VERSION "GT86 bus: what the GT86-ISF gateway sends (generated by tools/generate.py)"

NS_ :

BS_:

BU_: GATEWAY ADU GT86

BO_ 208 GT86_GSensor: 8 GATEWAY

BO_ 209 GT86_VehicleSpeed: 8 GATEWAY
 SG_ VehicleSpeed : 0|16@1+ (0.0565,0) [0|3702.73] "km/h" GT86

BO_ 210 GT86_Unknown_D2: 8 GATEWAY

BO_ 211 GT86_LightStatus: 8 GATEWAY

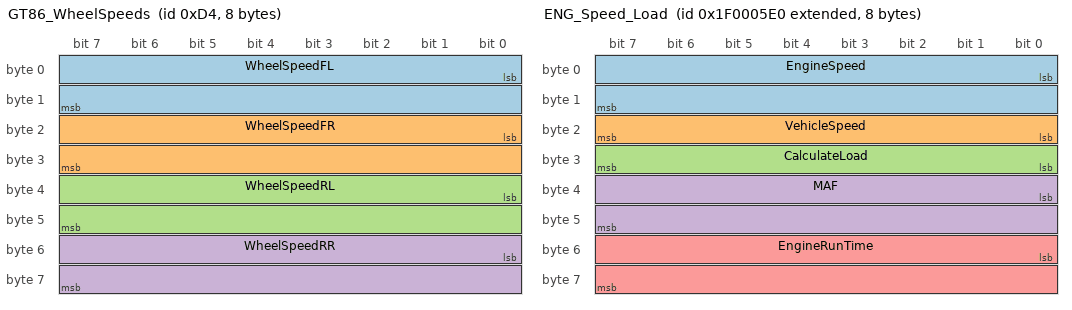
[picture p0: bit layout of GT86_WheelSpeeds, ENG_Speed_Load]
BO_ 212 GT86_WheelSpeeds: 8 GATEWAY
 SG_ WheelSpeedFL : 0|16@1+ (0.0565,0) [0|3702.73] "km/h" GT86
 SG_ WheelSpeedFR : 16|16@1+ (0.0565,0) [0|3702.73] "km/h" GT86
 SG_ WheelSpeedRL : 32|16@1+ (0.0565,0) [0|3702.73] "km/h" GT86
 SG_ WheelSpeedRR : 48|16@1+ (0.0565,0) [0|3702.73] "km/h" GT86

BO_ 320 GT86_EngineData1: 8 GATEWAY

BO_ 321 GT86_EngineData2: 8 GATEWAY
 SG_ EngineRPM : 32|14@1+ (1,0) [0|16383] "rpm" GT86

BO_ 322 GT86_EngineMisc: 8 GATEWAY

BO_ 324 GT86_BrakeData1: 8 GATEWAY

BO_ 864 GT86_Temperatures: 8 GATEWAY
 SG_ EngineOilTemperature : 16|8@1+ (1,-40) [-40|215] "degC" GT86
 SG_ CoolantTemperature : 24|8@1+ (1,-40) [-40|215] "degC" GT86

BO_ 865 GT86_GearData2: 8 GATEWAY

BO_ 880 GT86_SteeringTorque2: 8 GATEWAY

BO_ 1224 GT86_Unknown_4C8: 8 GATEWAY

BO_ 1953 GT86_ClusterDiagRequest: 8 GATEWAY

BO_ 1961 GT86_ClusterDiagResponse: 8 GATEWAY

BO_ 2667578848 ENG_Speed_Load: 8 GATEWAY
 SG_ EngineSpeed : 0|16@1+ (0.25,0) [0|16383.8] "rpm" ADU
 SG_ VehicleSpeed : 16|8@1+ (1,0) [0|255] "km/h" ADU
 SG_ CalculateLoad : 24|8@1+ (0.39215686274509803,0) [0|100] "%" ADU
 SG_ MAF : 32|16@1+ (0.01,0) [0|655.35] "g/s" ADU
 SG_ EngineRunTime : 48|16@1+ (1,0) [0|65535] "s" ADU

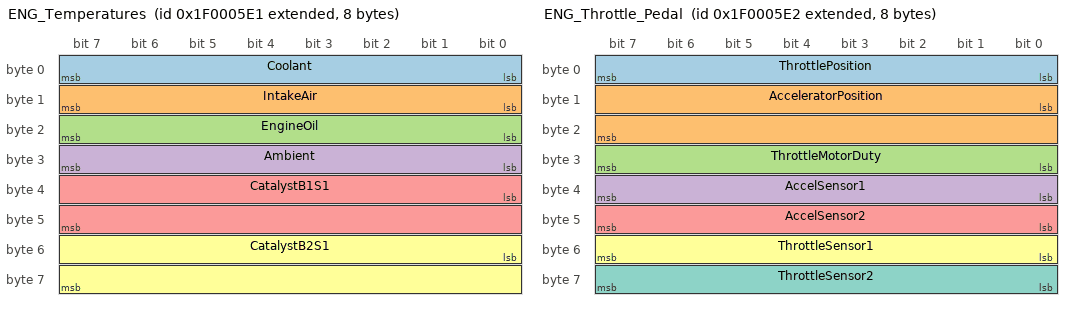
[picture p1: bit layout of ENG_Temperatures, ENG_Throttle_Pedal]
BO_ 2667578849 ENG_Temperatures: 8 GATEWAY
 SG_ Coolant : 0|8@1+ (1,-40) [-40|215] "degC" ADU
 SG_ IntakeAir : 8|8@1+ (1,-40) [-40|215] "degC" ADU
 SG_ EngineOil : 16|8@1+ (1,-40) [-40|215] "degC" ADU
 SG_ Ambient : 24|8@1+ (1,-40) [-40|215] "degC" ADU
 SG_ CatalystB1S1 : 32|16@1+ (0.1,-40) [-40|6513.5] "degC" ADU
 SG_ CatalystB2S1 : 48|16@1+ (0.1,-40) [-40|6513.5] "degC" ADU

BO_ 2667578850 ENG_Throttle_Pedal: 8 GATEWAY
 SG_ ThrottlePosition : 0|8@1+ (0.39215686274509803,0) [0|100] "%" ADU
 SG_ AcceleratorPosition : 8|16@1+ (0.006103515625,0) [0|399.994] "%" ADU
 SG_ ThrottleMotorDuty : 24|8@1+ (0.39215686274509803,0) [0|100] "%" ADU
 SG_ AccelSensor1 : 32|8@1+ (0.39215686274509803,0) [0|100] "%" ADU
 SG_ AccelSensor2 : 40|8@1+ (0.39215686274509803,0) [0|100] "%" ADU
 SG_ ThrottleSensor1 : 48|8@1+ (0.39215686274509803,0) [0|100] "%" ADU
 SG_ ThrottleSensor2 : 56|8@1+ (0.39215686274509803,0) [0|100] "%" ADU

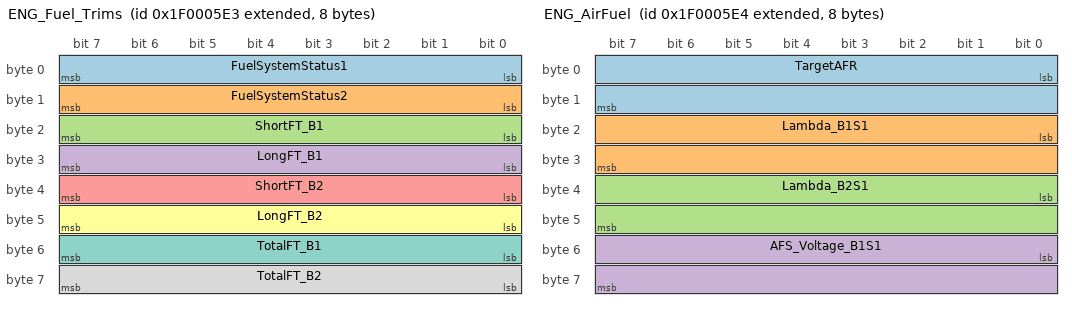
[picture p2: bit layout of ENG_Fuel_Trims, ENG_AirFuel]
BO_ 2667578851 ENG_Fuel_Trims: 8 GATEWAY
 SG_ FuelSystemStatus1 : 0|8@1+ (1,0) [0|255] "" ADU
 SG_ FuelSystemStatus2 : 8|8@1+ (1,0) [0|255] "" ADU
 SG_ ShortFT_B1 : 16|8@1+ (0.78125,-100) [-100|99.2188] "%" ADU
 SG_ LongFT_B1 : 24|8@1+ (0.78125,-100) [-100|99.2188] "%" ADU
 SG_ ShortFT_B2 : 32|8@1+ (0.78125,-100) [-100|99.2188] "%" ADU
 SG_ LongFT_B2 : 40|8@1+ (0.78125,-100) [-100|99.2188] "%" ADU
 SG_ TotalFT_B1 : 48|8@1+ (0.00390625,-0.5) [-0.5|0.496094] "" ADU
 SG_ TotalFT_B2 : 56|8@1+ (0.00390625,-0.5) [-0.5|0.496094] "" ADU

BO_ 2667578852 ENG_AirFuel: 8 GATEWAY
 SG_ TargetAFR : 0|16@1+ (3.05e-05,0) [0|1.99882] "" ADU
 SG_ Lambda_B1S1 : 16|16@1+ (3.05e-05,0) [0|1.99882] "" ADU
 SG_ Lambda_B2S1 : 32|16@1+ (3.05e-05,0) [0|1.99882] "" ADU
 SG_ AFS_Voltage_B1S1 : 48|16@1+ (0.000122,0) [0|7.99527] "V" ADU

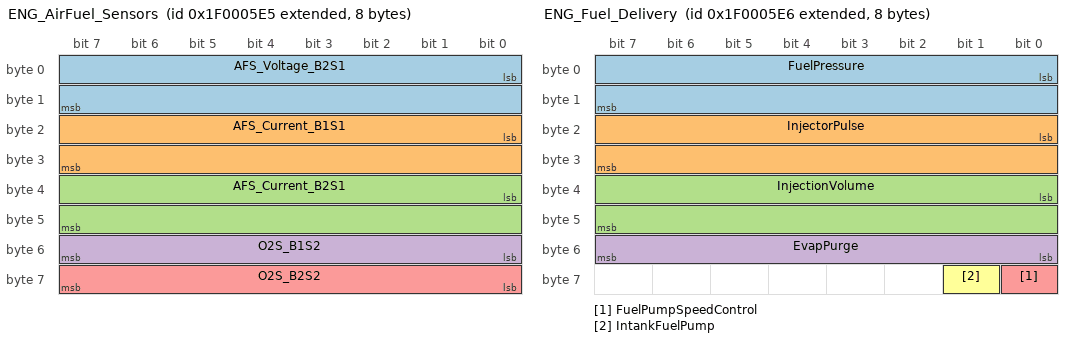
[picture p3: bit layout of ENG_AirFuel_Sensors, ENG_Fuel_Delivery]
BO_ 2667578853 ENG_AirFuel_Sensors: 8 GATEWAY
 SG_ AFS_Voltage_B2S1 : 0|16@1+ (0.000122,0) [0|7.99527] "V" ADU
 SG_ AFS_Current_B1S1 : 16|16@1+ (0.00390625,-128) [-128|127.996] "mA" ADU
 SG_ AFS_Current_B2S1 : 32|16@1+ (0.00390625,-128) [-128|127.996] "mA" ADU
 SG_ O2S_B1S2 : 48|8@1+ (0.005,0) [0|1.275] "V" ADU
 SG_ O2S_B2S2 : 56|8@1+ (0.005,0) [0|1.275] "V" ADU

BO_ 2667578854 ENG_Fuel_Delivery: 8 GATEWAY
 SG_ FuelPressure : 0|16@1+ (10,0) [0|655350] "kPa" ADU
 SG_ InjectorPulse : 16|16@1+ (1,0) [0|65535] "us" ADU
 SG_ InjectionVolume : 32|16@1+ (3.125e-05,0) [0|2.04797] "ml" ADU
 SG_ EvapPurge : 48|8@1+ (0.39215686274509803,0) [0|100] "%" ADU
 SG_ FuelPumpSpeedControl : 56|1@1+ (1,0) [0|1] "" ADU
 SG_ IntankFuelPump : 57|1@1+ (1,0) [0|1] "" ADU

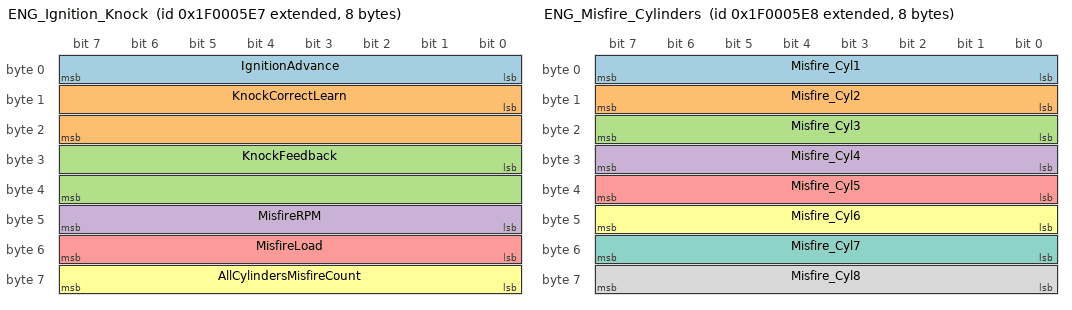
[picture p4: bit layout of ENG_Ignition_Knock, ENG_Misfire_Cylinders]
BO_ 2667578855 ENG_Ignition_Knock: 8 GATEWAY
 SG_ IgnitionAdvance : 0|8@1+ (0.5,-64) [-64|63.5] "deg" ADU
 SG_ KnockCorrectLearn : 8|16@1+ (0.03125,-1024) [-1024|1023.97] "deg" ADU
 SG_ KnockFeedback : 24|16@1+ (0.03125,-1024) [-1024|1023.97] "deg" ADU
 SG_ MisfireRPM : 40|8@1+ (25,0) [0|6375] "rpm" ADU
 SG_ MisfireLoad : 48|8@1+ (0.015625,0) [0|3.98438] "g/rev" ADU
 SG_ AllCylindersMisfireCount : 56|8@1+ (1,0) [0|255] "" ADU

BO_ 2667578856 ENG_Misfire_Cylinders: 8 GATEWAY
 SG_ Misfire_Cyl1 : 0|8@1+ (1,0) [0|255] "" ADU
 SG_ Misfire_Cyl2 : 8|8@1+ (1,0) [0|255] "" ADU
 SG_ Misfire_Cyl3 : 16|8@1+ (1,0) [0|255] "" ADU
 SG_ Misfire_Cyl4 : 24|8@1+ (1,0) [0|255] "" ADU
 SG_ Misfire_Cyl5 : 32|8@1+ (1,0) [0|255] "" ADU
 SG_ Misfire_Cyl6 : 40|8@1+ (1,0) [0|255] "" ADU
 SG_ Misfire_Cyl7 : 48|8@1+ (1,0) [0|255] "" ADU
 SG_ Misfire_Cyl8 : 56|8@1+ (1,0) [0|255] "" ADU

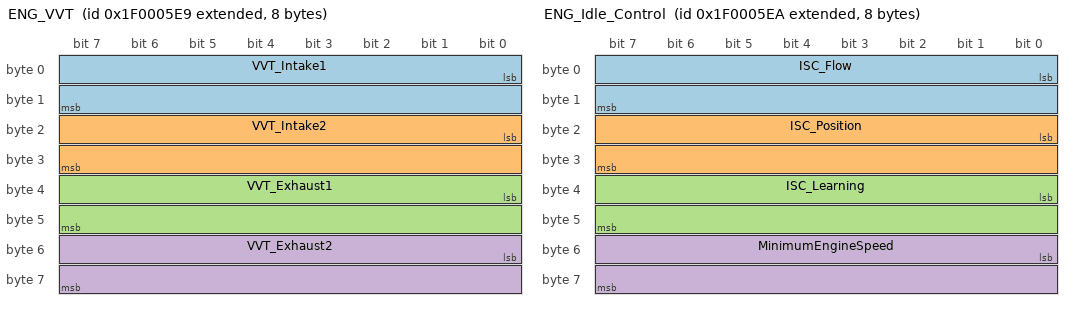
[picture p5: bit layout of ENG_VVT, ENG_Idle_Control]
BO_ 2667578857 ENG_VVT: 8 GATEWAY
 SG_ VVT_Intake1 : 0|16@1+ (0.009765625,0) [0|639.99] "deg" ADU
 SG_ VVT_Intake2 : 16|16@1+ (0.009765625,0) [0|639.99] "deg" ADU
 SG_ VVT_Exhaust1 : 32|16@1+ (0.009765625,0) [0|639.99] "deg" ADU
 SG_ VVT_Exhaust2 : 48|16@1+ (0.009765625,0) [0|639.99] "deg" ADU

BO_ 2667578858 ENG_Idle_Control: 8 GATEWAY
 SG_ ISC_Flow : 0|16@1+ (0.001220703125,0) [0|79.9988] "m3/s" ADU
 SG_ ISC_Position : 16|16@1+ (0.00762939453125,0) [0|499.992] "deg" ADU
 SG_ ISC_Learning : 32|16@1+ (0.001220703125,-40) [-40|39.9988] "m3/s" ADU
 SG_ MinimumEngineSpeed : 48|16@1+ (0.78125,0) [0|51199.2] "rpm" ADU

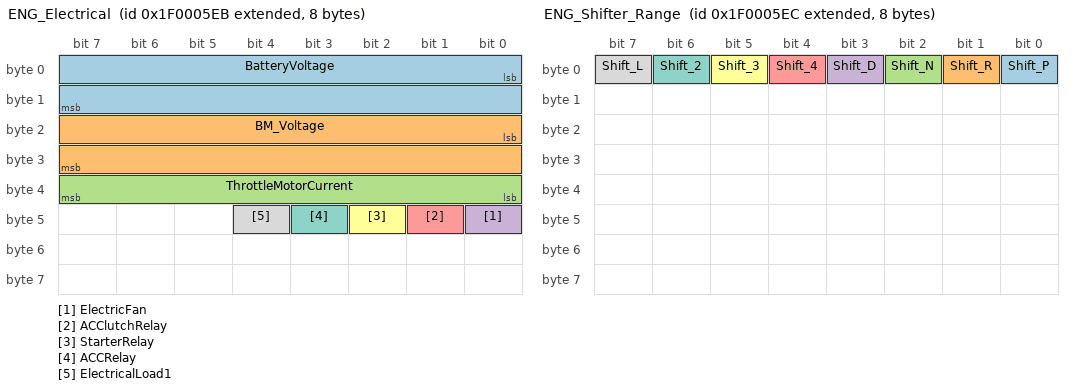
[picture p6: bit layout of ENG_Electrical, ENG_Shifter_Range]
BO_ 2667578859 ENG_Electrical: 8 GATEWAY
 SG_ BatteryVoltage : 0|16@1+ (0.001,0) [0|65.535] "V" ADU
 SG_ BM_Voltage : 16|16@1+ (0.001220703125,0) [0|79.9988] "V" ADU
 SG_ ThrottleMotorCurrent : 32|8@1+ (0.078125,0) [0|19.9219] "A" ADU
 SG_ ElectricFan : 40|1@1+ (1,0) [0|1] "" ADU
 SG_ ACClutchRelay : 41|1@1+ (1,0) [0|1] "" ADU
 SG_ StarterRelay : 42|1@1+ (1,0) [0|1] "" ADU
 SG_ ACCRelay : 43|1@1+ (1,0) [0|1] "" ADU
 SG_ ElectricalLoad1 : 44|1@1+ (1,0) [0|1] "" ADU

BO_ 2667578860 ENG_Shifter_Range: 8 GATEWAY
 SG_ Shift_P : 0|1@1+ (1,0) [0|1] "" ADU
 SG_ Shift_R : 1|1@1+ (1,0) [0|1] "" ADU
 SG_ Shift_N : 2|1@1+ (1,0) [0|1] "" ADU
 SG_ Shift_D : 3|1@1+ (1,0) [0|1] "" ADU
 SG_ Shift_4 : 4|1@1+ (1,0) [0|1] "" ADU
 SG_ Shift_3 : 5|1@1+ (1,0) [0|1] "" ADU
 SG_ Shift_2 : 6|1@1+ (1,0) [0|1] "" ADU
 SG_ Shift_L : 7|1@1+ (1,0) [0|1] "" ADU

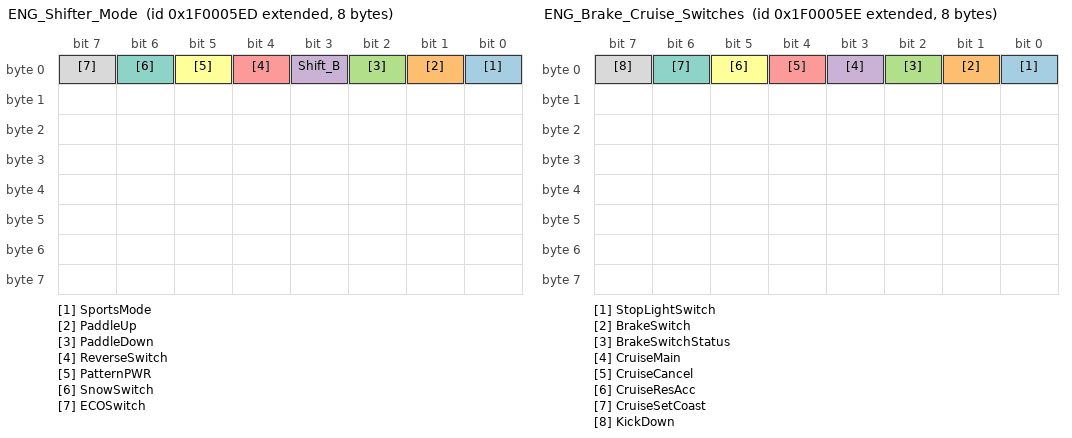
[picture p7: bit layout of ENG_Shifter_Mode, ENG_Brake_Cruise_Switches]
BO_ 2667578861 ENG_Shifter_Mode: 8 GATEWAY
 SG_ SportsMode : 0|1@1+ (1,0) [0|1] "" ADU
 SG_ PaddleUp : 1|1@1+ (1,0) [0|1] "" ADU
 SG_ PaddleDown : 2|1@1+ (1,0) [0|1] "" ADU
 SG_ Shift_B : 3|1@1+ (1,0) [0|1] "" ADU
 SG_ ReverseSwitch : 4|1@1+ (1,0) [0|1] "" ADU
 SG_ PatternPWR : 5|1@1+ (1,0) [0|1] "" ADU
 SG_ SnowSwitch : 6|1@1+ (1,0) [0|1] "" ADU
 SG_ ECOSwitch : 7|1@1+ (1,0) [0|1] "" ADU

BO_ 2667578862 ENG_Brake_Cruise_Switches: 8 GATEWAY
 SG_ StopLightSwitch : 0|1@1+ (1,0) [0|1] "" ADU
 SG_ BrakeSwitch : 1|1@1+ (1,0) [0|1] "" ADU
 SG_ BrakeSwitchStatus : 2|1@1+ (1,0) [0|1] "" ADU
 SG_ CruiseMain : 3|1@1+ (1,0) [0|1] "" ADU
 SG_ CruiseCancel : 4|1@1+ (1,0) [0|1] "" ADU
 SG_ CruiseResAcc : 5|1@1+ (1,0) [0|1] "" ADU
 SG_ CruiseSetCoast : 6|1@1+ (1,0) [0|1] "" ADU
 SG_ KickDown : 7|1@1+ (1,0) [0|1] "" ADU

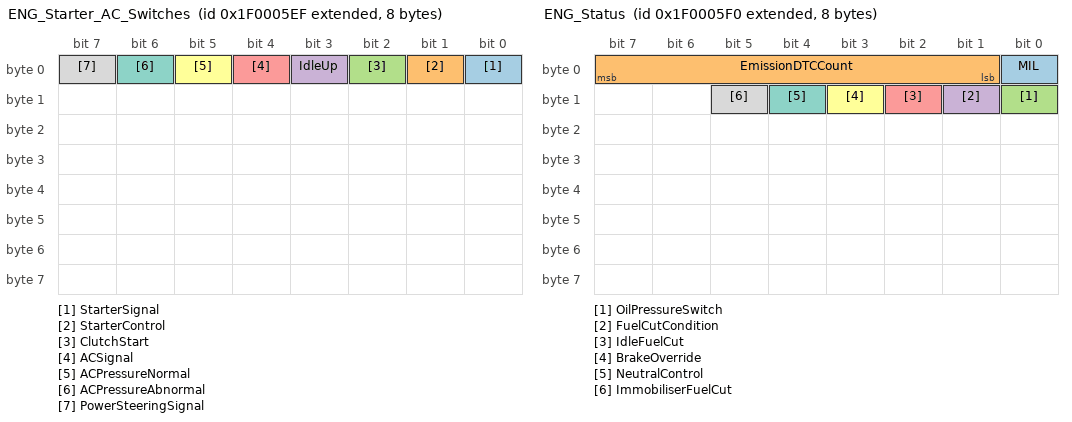
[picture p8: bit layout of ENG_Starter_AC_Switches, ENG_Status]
BO_ 2667578863 ENG_Starter_AC_Switches: 8 GATEWAY
 SG_ StarterSignal : 0|1@1+ (1,0) [0|1] "" ADU
 SG_ StarterControl : 1|1@1+ (1,0) [0|1] "" ADU
 SG_ ClutchStart : 2|1@1+ (1,0) [0|1] "" ADU
 SG_ IdleUp : 3|1@1+ (1,0) [0|1] "" ADU
 SG_ ACSignal : 4|1@1+ (1,0) [0|1] "" ADU
 SG_ ACPressureNormal : 5|1@1+ (1,0) [0|1] "" ADU
 SG_ ACPressureAbnormal : 6|1@1+ (1,0) [0|1] "" ADU
 SG_ PowerSteeringSignal : 7|1@1+ (1,0) [0|1] "" ADU

BO_ 2667578864 ENG_Status: 8 GATEWAY
 SG_ MIL : 0|1@1+ (1,0) [0|1] "" ADU
 SG_ EmissionDTCCount : 1|7@1+ (1,0) [0|127] "" ADU
 SG_ OilPressureSwitch : 8|1@1+ (1,0) [0|1] "" ADU
 SG_ FuelCutCondition : 9|1@1+ (1,0) [0|1] "" ADU
 SG_ IdleFuelCut : 10|1@1+ (1,0) [0|1] "" ADU
 SG_ BrakeOverride : 11|1@1+ (1,0) [0|1] "" ADU
 SG_ NeutralControl : 12|1@1+ (1,0) [0|1] "" ADU
 SG_ ImmobiliserFuelCut : 13|1@1+ (1,0) [0|1] "" ADU

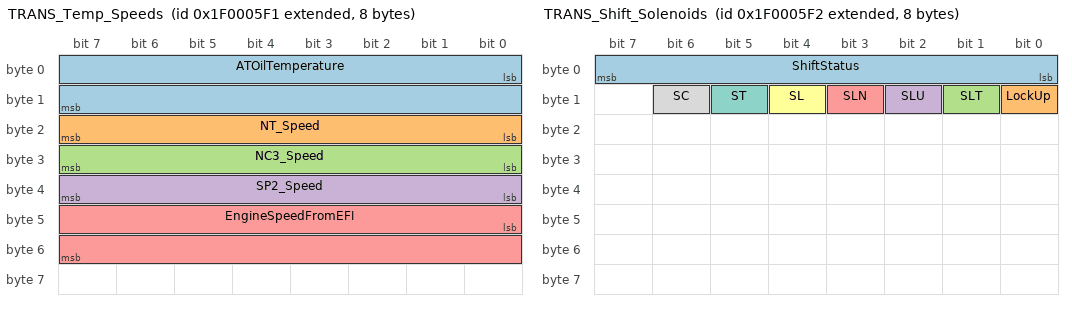
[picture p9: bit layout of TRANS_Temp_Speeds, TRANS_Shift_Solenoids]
BO_ 2667578865 TRANS_Temp_Speeds: 8 GATEWAY
 SG_ ATOilTemperature : 0|16@1+ (0.00390625,-40) [-40|215.996] "degC" ADU
 SG_ NT_Speed : 16|8@1+ (50,0) [0|12750] "rpm" ADU
 SG_ NC3_Speed : 24|8@1+ (50,0) [0|12750] "rpm" ADU
 SG_ SP2_Speed : 32|8@1+ (1,0) [0|255] "km/h" ADU
 SG_ EngineSpeedFromEFI : 40|16@1+ (0.78125,0) [0|51199.2] "rpm" ADU

BO_ 2667578866 TRANS_Shift_Solenoids: 8 GATEWAY
 SG_ ShiftStatus : 0|8@1+ (1,0) [0|255] "" ADU
 SG_ LockUp : 8|1@1+ (1,0) [0|1] "" ADU
 SG_ SLT : 9|1@1+ (1,0) [0|1] "" ADU
 SG_ SLU : 10|1@1+ (1,0) [0|1] "" ADU
 SG_ SLN : 11|1@1+ (1,0) [0|1] "" ADU
 SG_ SL : 12|1@1+ (1,0) [0|1] "" ADU
 SG_ ST : 13|1@1+ (1,0) [0|1] "" ADU
 SG_ SC : 14|1@1+ (1,0) [0|1] "" ADU

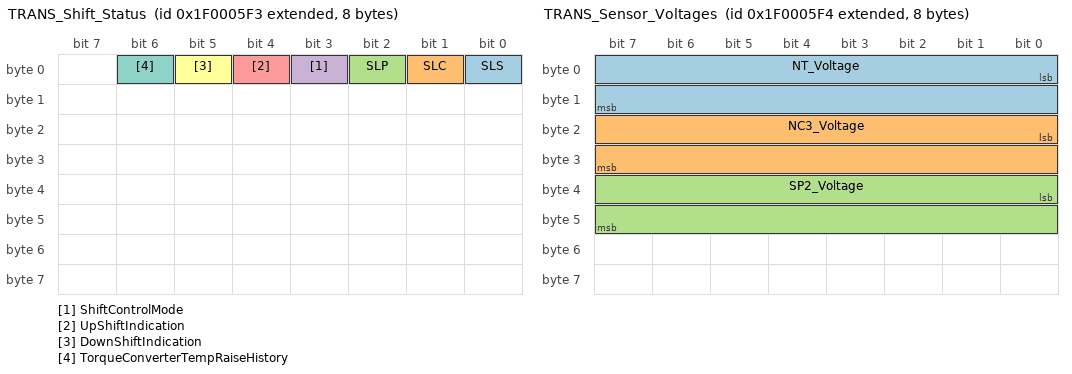
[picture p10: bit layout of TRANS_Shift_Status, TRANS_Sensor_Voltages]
BO_ 2667578867 TRANS_Shift_Status: 8 GATEWAY
 SG_ SLS : 0|1@1+ (1,0) [0|1] "" ADU
 SG_ SLC : 1|1@1+ (1,0) [0|1] "" ADU
 SG_ SLP : 2|1@1+ (1,0) [0|1] "" ADU
 SG_ ShiftControlMode : 3|1@1+ (1,0) [0|1] "" ADU
 SG_ UpShiftIndication : 4|1@1+ (1,0) [0|1] "" ADU
 SG_ DownShiftIndication : 5|1@1+ (1,0) [0|1] "" ADU
 SG_ TorqueConverterTempRaiseHistory : 6|1@1+ (1,0) [0|1] "" ADU

BO_ 2667578868 TRANS_Sensor_Voltages: 8 GATEWAY
 SG_ NT_Voltage : 0|16@1+ (7.62939453125e-05,0) [0|4.99992] "V" ADU
 SG_ NC3_Voltage : 16|16@1+ (7.62939453125e-05,0) [0|4.99992] "V" ADU
 SG_ SP2_Voltage : 32|16@1+ (7.62939453125e-05,0) [0|4.99992] "V" ADU

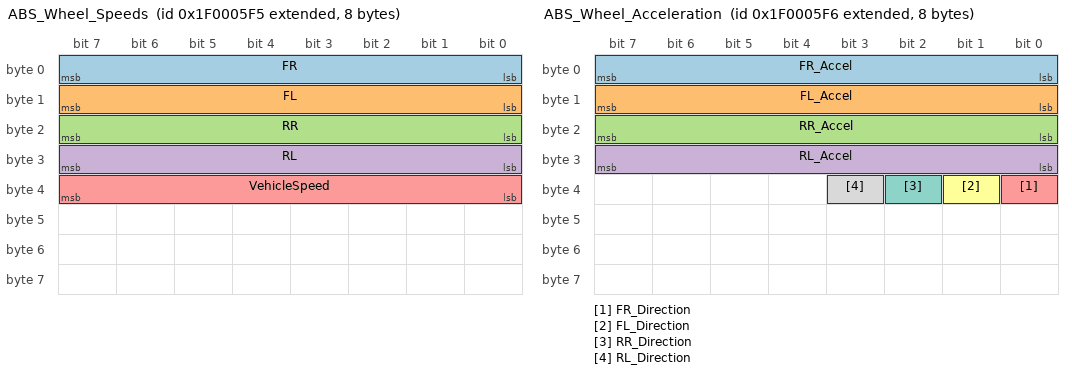
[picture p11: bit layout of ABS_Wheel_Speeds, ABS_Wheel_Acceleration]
BO_ 2667578869 ABS_Wheel_Speeds: 8 GATEWAY
 SG_ FR : 0|8@1+ (1.28,0) [0|326.4] "km/h" ADU
 SG_ FL : 8|8@1+ (1.28,0) [0|326.4] "km/h" ADU
 SG_ RR : 16|8@1+ (1.28,0) [0|326.4] "km/h" ADU
 SG_ RL : 24|8@1+ (1.28,0) [0|326.4] "km/h" ADU
 SG_ VehicleSpeed : 32|8@1+ (1.28,0) [0|326.4] "km/h" ADU

BO_ 2667578870 ABS_Wheel_Acceleration: 8 GATEWAY
 SG_ FR_Accel : 0|8@1- (1.569064,0) [-200.84|199.271] "m/s2" ADU
 SG_ FL_Accel : 8|8@1- (1.569064,0) [-200.84|199.271] "m/s2" ADU
 SG_ RR_Accel : 16|8@1- (1.569064,0) [-200.84|199.271] "m/s2" ADU
 SG_ RL_Accel : 24|8@1- (1.569064,0) [-200.84|199.271] "m/s2" ADU
 SG_ FR_Direction : 32|1@1+ (1,0) [0|1] "" ADU
 SG_ FL_Direction : 33|1@1+ (1,0) [0|1] "" ADU
 SG_ RR_Direction : 34|1@1+ (1,0) [0|1] "" ADU
 SG_ RL_Direction : 35|1@1+ (1,0) [0|1] "" ADU

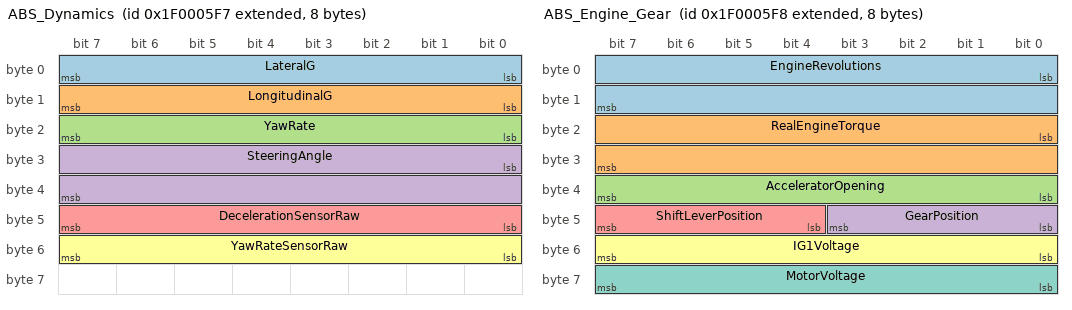
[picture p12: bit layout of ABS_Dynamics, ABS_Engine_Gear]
BO_ 2667578871 ABS_Dynamics: 8 GATEWAY
 SG_ LateralG : 0|8@1- (0.196133,0) [-25.105|24.9089] "m/s2" ADU
 SG_ LongitudinalG : 8|8@1- (0.196133,0) [-25.105|24.9089] "m/s2" ADU
 SG_ YawRate : 16|8@1+ (1,-128) [-128|127] "deg/s" ADU
 SG_ SteeringAngle : 24|16@1+ (0.1,-3276.8) [-3276.8|3276.7] "deg" ADU
 SG_ DecelerationSensorRaw : 40|8@1+ (0.14318,-18.327) [-18.327|18.1839] "m/s2" ADU
 SG_ YawRateSensorRaw : 48|8@1+ (1,-128) [-128|127] "deg/s" ADU

BO_ 2667578872 ABS_Engine_Gear: 8 GATEWAY
 SG_ EngineRevolutions : 0|16@1+ (1,0) [0|65535] "rpm" ADU
 SG_ RealEngineTorque : 16|16@1- (0.03125,0) [-1024|1023.97] "Nm" ADU
 SG_ AcceleratorOpening : 32|8@1+ (0.5,0) [0|127.5] "%" ADU
 SG_ GearPosition : 40|4@1+ (1,0) [0|15] "" ADU
 SG_ ShiftLeverPosition : 44|4@1+ (1,0) [0|15] "" ADU
 SG_ IG1Voltage : 48|8@1+ (0.0784313725490196,0) [0|20] "V" ADU
 SG_ MotorVoltage : 56|8@1+ (0.0784313725490196,0) [0|20] "V" ADU

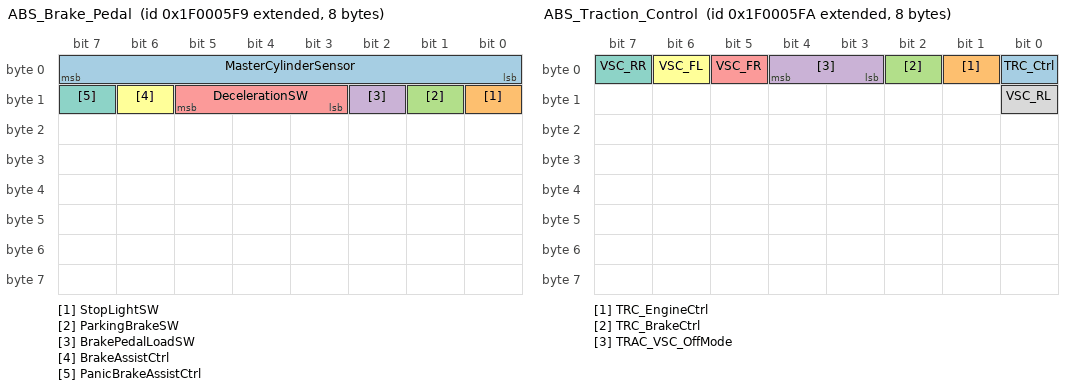
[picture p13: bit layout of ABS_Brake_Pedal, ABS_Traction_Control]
BO_ 2667578873 ABS_Brake_Pedal: 8 GATEWAY
 SG_ MasterCylinderSensor : 0|8@1+ (0.0196078431372549,0) [0|5] "V" ADU
 SG_ StopLightSW : 8|1@1+ (1,0) [0|1] "" ADU
 SG_ ParkingBrakeSW : 9|1@1+ (1,0) [0|1] "" ADU
 SG_ BrakePedalLoadSW : 10|1@1+ (1,0) [0|1] "" ADU
 SG_ DecelerationSW : 11|3@1+ (1,0) [0|7] "" ADU
 SG_ BrakeAssistCtrl : 14|1@1+ (1,0) [0|1] "" ADU
 SG_ PanicBrakeAssistCtrl : 15|1@1+ (1,0) [0|1] "" ADU

BO_ 2667578874 ABS_Traction_Control: 8 GATEWAY
 SG_ TRC_Ctrl : 0|1@1+ (1,0) [0|1] "" ADU
 SG_ TRC_EngineCtrl : 1|1@1+ (1,0) [0|1] "" ADU
 SG_ TRC_BrakeCtrl : 2|1@1+ (1,0) [0|1] "" ADU
 SG_ TRAC_VSC_OffMode : 3|2@1+ (1,0) [0|3] "" ADU
 SG_ VSC_FR : 5|1@1+ (1,0) [0|1] "" ADU
 SG_ VSC_FL : 6|1@1+ (1,0) [0|1] "" ADU
 SG_ VSC_RR : 7|1@1+ (1,0) [0|1] "" ADU
 SG_ VSC_RL : 8|1@1+ (1,0) [0|1] "" ADU

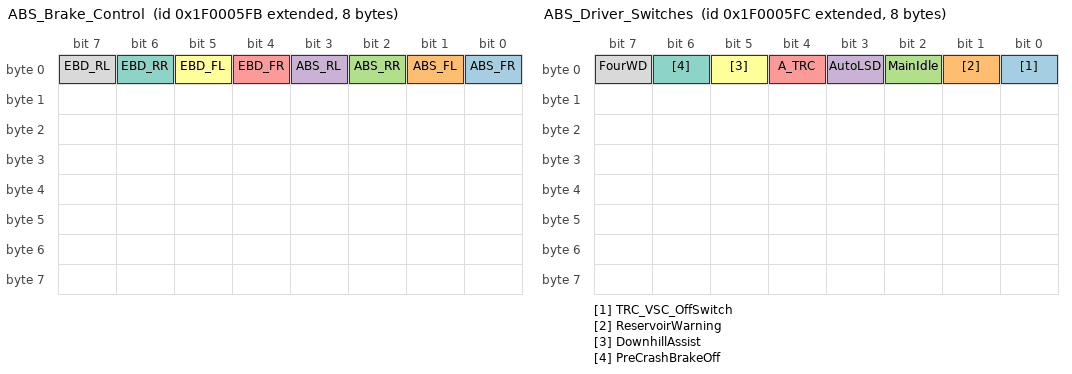
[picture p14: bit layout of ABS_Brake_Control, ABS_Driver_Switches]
BO_ 2667578875 ABS_Brake_Control: 8 GATEWAY
 SG_ ABS_FR : 0|1@1+ (1,0) [0|1] "" ADU
 SG_ ABS_FL : 1|1@1+ (1,0) [0|1] "" ADU
 SG_ ABS_RR : 2|1@1+ (1,0) [0|1] "" ADU
 SG_ ABS_RL : 3|1@1+ (1,0) [0|1] "" ADU
 SG_ EBD_FR : 4|1@1+ (1,0) [0|1] "" ADU
 SG_ EBD_FL : 5|1@1+ (1,0) [0|1] "" ADU
 SG_ EBD_RR : 6|1@1+ (1,0) [0|1] "" ADU
 SG_ EBD_RL : 7|1@1+ (1,0) [0|1] "" ADU

BO_ 2667578876 ABS_Driver_Switches: 8 GATEWAY
 SG_ TRC_VSC_OffSwitch : 0|1@1+ (1,0) [0|1] "" ADU
 SG_ ReservoirWarning : 1|1@1+ (1,0) [0|1] "" ADU
 SG_ MainIdle : 2|1@1+ (1,0) [0|1] "" ADU
 SG_ AutoLSD : 3|1@1+ (1,0) [0|1] "" ADU
 SG_ A_TRC : 4|1@1+ (1,0) [0|1] "" ADU
 SG_ DownhillAssist : 5|1@1+ (1,0) [0|1] "" ADU
 SG_ PreCrashBrakeOff : 6|1@1+ (1,0) [0|1] "" ADU
 SG_ FourWD : 7|1@1+ (1,0) [0|1] "" ADU

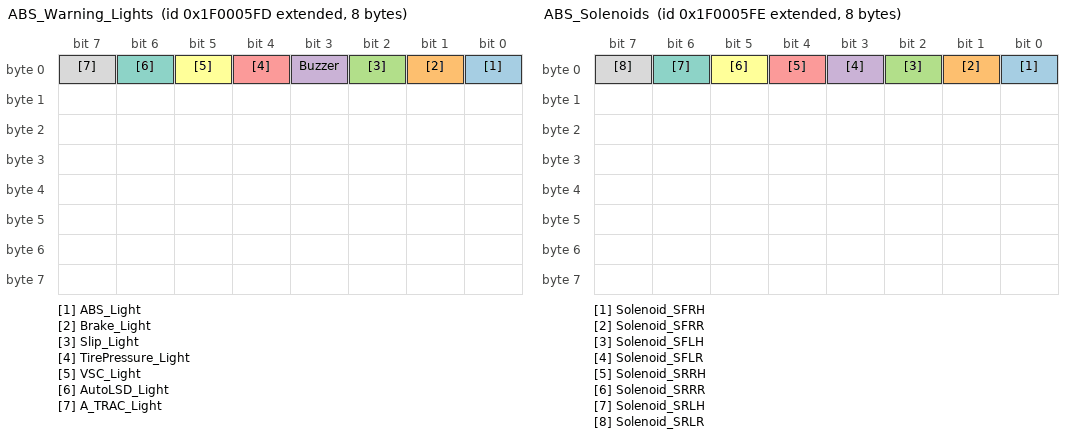
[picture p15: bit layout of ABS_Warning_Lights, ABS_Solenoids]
BO_ 2667578877 ABS_Warning_Lights: 8 GATEWAY
 SG_ ABS_Light : 0|1@1+ (1,0) [0|1] "" ADU
 SG_ Brake_Light : 1|1@1+ (1,0) [0|1] "" ADU
 SG_ Slip_Light : 2|1@1+ (1,0) [0|1] "" ADU
 SG_ Buzzer : 3|1@1+ (1,0) [0|1] "" ADU
 SG_ TirePressure_Light : 4|1@1+ (1,0) [0|1] "" ADU
 SG_ VSC_Light : 5|1@1+ (1,0) [0|1] "" ADU
 SG_ AutoLSD_Light : 6|1@1+ (1,0) [0|1] "" ADU
 SG_ A_TRAC_Light : 7|1@1+ (1,0) [0|1] "" ADU

BO_ 2667578878 ABS_Solenoids: 8 GATEWAY
 SG_ Solenoid_SFRH : 0|1@1+ (1,0) [0|1] "" ADU
 SG_ Solenoid_SFRR : 1|1@1+ (1,0) [0|1] "" ADU
 SG_ Solenoid_SFLH : 2|1@1+ (1,0) [0|1] "" ADU
 SG_ Solenoid_SFLR : 3|1@1+ (1,0) [0|1] "" ADU
 SG_ Solenoid_SRRH : 4|1@1+ (1,0) [0|1] "" ADU
 SG_ Solenoid_SRRR : 5|1@1+ (1,0) [0|1] "" ADU
 SG_ Solenoid_SRLH : 6|1@1+ (1,0) [0|1] "" ADU
 SG_ Solenoid_SRLR : 7|1@1+ (1,0) [0|1] "" ADU

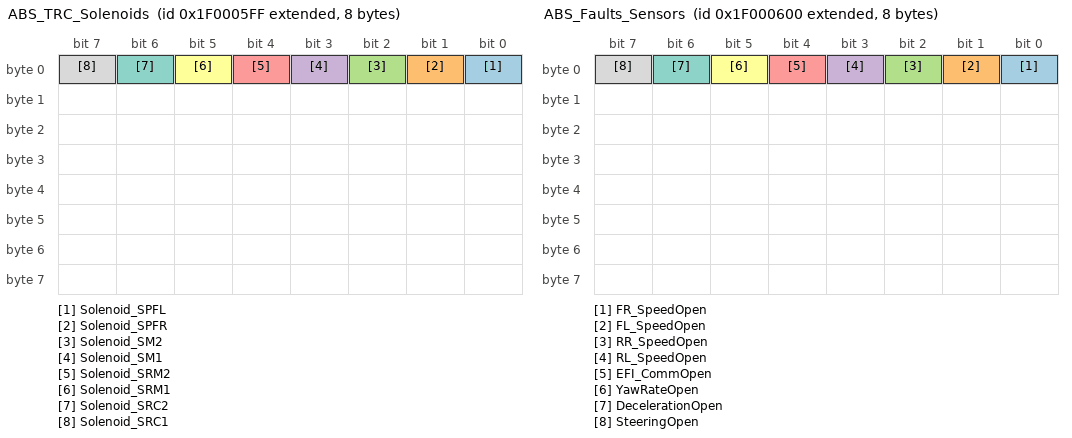
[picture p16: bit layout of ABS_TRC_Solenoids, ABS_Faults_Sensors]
BO_ 2667578879 ABS_TRC_Solenoids: 8 GATEWAY
 SG_ Solenoid_SPFL : 0|1@1+ (1,0) [0|1] "" ADU
 SG_ Solenoid_SPFR : 1|1@1+ (1,0) [0|1] "" ADU
 SG_ Solenoid_SM2 : 2|1@1+ (1,0) [0|1] "" ADU
 SG_ Solenoid_SM1 : 3|1@1+ (1,0) [0|1] "" ADU
 SG_ Solenoid_SRM2 : 4|1@1+ (1,0) [0|1] "" ADU
 SG_ Solenoid_SRM1 : 5|1@1+ (1,0) [0|1] "" ADU
 SG_ Solenoid_SRC2 : 6|1@1+ (1,0) [0|1] "" ADU
 SG_ Solenoid_SRC1 : 7|1@1+ (1,0) [0|1] "" ADU

BO_ 2667578880 ABS_Faults_Sensors: 8 GATEWAY
 SG_ FR_SpeedOpen : 0|1@1+ (1,0) [0|1] "" ADU
 SG_ FL_SpeedOpen : 1|1@1+ (1,0) [0|1] "" ADU
 SG_ RR_SpeedOpen : 2|1@1+ (1,0) [0|1] "" ADU
 SG_ RL_SpeedOpen : 3|1@1+ (1,0) [0|1] "" ADU
 SG_ EFI_CommOpen : 4|1@1+ (1,0) [0|1] "" ADU
 SG_ YawRateOpen : 5|1@1+ (1,0) [0|1] "" ADU
 SG_ DecelerationOpen : 6|1@1+ (1,0) [0|1] "" ADU
 SG_ SteeringOpen : 7|1@1+ (1,0) [0|1] "" ADU

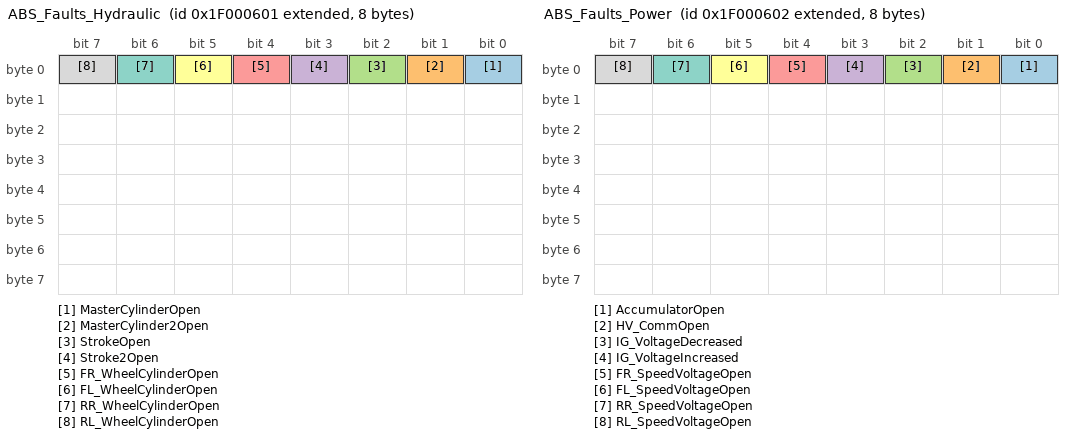
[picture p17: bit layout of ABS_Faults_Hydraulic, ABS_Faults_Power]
BO_ 2667578881 ABS_Faults_Hydraulic: 8 GATEWAY
 SG_ MasterCylinderOpen : 0|1@1+ (1,0) [0|1] "" ADU
 SG_ MasterCylinder2Open : 1|1@1+ (1,0) [0|1] "" ADU
 SG_ StrokeOpen : 2|1@1+ (1,0) [0|1] "" ADU
 SG_ Stroke2Open : 3|1@1+ (1,0) [0|1] "" ADU
 SG_ FR_WheelCylinderOpen : 4|1@1+ (1,0) [0|1] "" ADU
 SG_ FL_WheelCylinderOpen : 5|1@1+ (1,0) [0|1] "" ADU
 SG_ RR_WheelCylinderOpen : 6|1@1+ (1,0) [0|1] "" ADU
 SG_ RL_WheelCylinderOpen : 7|1@1+ (1,0) [0|1] "" ADU

BO_ 2667578882 ABS_Faults_Power: 8 GATEWAY
 SG_ AccumulatorOpen : 0|1@1+ (1,0) [0|1] "" ADU
 SG_ HV_CommOpen : 1|1@1+ (1,0) [0|1] "" ADU
 SG_ IG_VoltageDecreased : 2|1@1+ (1,0) [0|1] "" ADU
 SG_ IG_VoltageIncreased : 3|1@1+ (1,0) [0|1] "" ADU
 SG_ FR_SpeedVoltageOpen : 4|1@1+ (1,0) [0|1] "" ADU
 SG_ FL_SpeedVoltageOpen : 5|1@1+ (1,0) [0|1] "" ADU
 SG_ RR_SpeedVoltageOpen : 6|1@1+ (1,0) [0|1] "" ADU
 SG_ RL_SpeedVoltageOpen : 7|1@1+ (1,0) [0|1] "" ADU

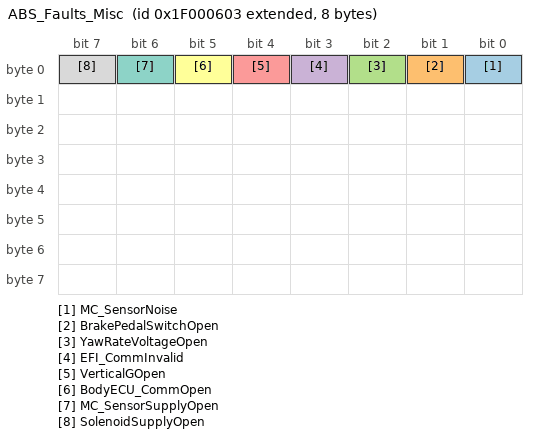
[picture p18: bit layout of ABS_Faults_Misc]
BO_ 2667578883 ABS_Faults_Misc: 8 GATEWAY
 SG_ MC_SensorNoise : 0|1@1+ (1,0) [0|1] "" ADU
 SG_ BrakePedalSwitchOpen : 1|1@1+ (1,0) [0|1] "" ADU
 SG_ YawRateVoltageOpen : 2|1@1+ (1,0) [0|1] "" ADU
 SG_ EFI_CommInvalid : 3|1@1+ (1,0) [0|1] "" ADU
 SG_ VerticalGOpen : 4|1@1+ (1,0) [0|1] "" ADU
 SG_ BodyECU_CommOpen : 5|1@1+ (1,0) [0|1] "" ADU
 SG_ MC_SensorSupplyOpen : 6|1@1+ (1,0) [0|1] "" ADU
 SG_ SolenoidSupplyOpen : 7|1@1+ (1,0) [0|1] "" ADU

CM_ BO_ 208 "Steering angle and lateral/longitudinal G; default bytes only: wheel straight, no G (the real car at rest sends 0E 00 01 00 00 00 00 FF)";
CM_ BO_ 209 "Vehicle speed (bytes 0-1, 0.0565 km/h per bit) and brake data; default is the real car at rest (00 00 13 00), foot off the brake";
CM_ BO_ 211 "VSC / TCS / SCS lights; default bytes only";
CM_ BO_ 212 "Four wheel speeds, 16 bits each, 0.0565 km/h per bit";
CM_ BO_ 320 "Default bytes only: bytes 2-3 did not move with engine speed in the drive capture";
CM_ BO_ 321 "Engine rpm in bits 32-45 (bytes 4-5, 14 bits, 1 rpm per bit); bits 46-47 kept from the default";
CM_ BO_ 324 "In the cluster capture but missing from the old Readme table";
CM_ BO_ 864 "Byte 2 engine oil temperature, byte 3 coolant temperature, both +40";
CM_ BO_ 2667578848 "From engine 21 01";
CM_ BO_ 2667578849 "From engine 21 01, engine 21 51, engine 21 05";
CM_ BO_ 2667578850 "From engine 21 01, engine 21 41";
CM_ BO_ 2667578851 "From engine 21 03, engine 21 3C";
CM_ BO_ 2667578852 "From engine 21 04";
CM_ BO_ 2667578853 "From engine 21 04";
CM_ BO_ 2667578854 "From engine 21 05, engine 21 3C, engine 21 03, engine 21 39";
CM_ BO_ 2667578855 "From engine 21 03, engine 21 37, engine 21 45";
CM_ BO_ 2667578856 "From engine 21 45";
CM_ BO_ 2667578857 "From engine 21 44";
CM_ BO_ 2667578858 "From engine 21 51, engine 21 52";
CM_ BO_ 2667578859 "From engine 21 01, engine 21 41, engine 21 39, engine 21 25";
CM_ BO_ 2667578860 "From engine 21 25";
CM_ BO_ 2667578861 "From engine 21 25";
CM_ BO_ 2667578862 "From engine 21 25, engine 21 21";
CM_ BO_ 2667578863 "From engine 21 25";
CM_ BO_ 2667578864 "From engine 21 06, engine 21 25, engine 21 37, engine 21 51";
CM_ BO_ 2667578865 "From ect 21 82, ect 21 81, ect 21 22";
CM_ BO_ 2667578866 "From ect 21 85";
CM_ BO_ 2667578867 "From ect 21 85, ect 21 83";
CM_ BO_ 2667578868 "From ect 21 81";
CM_ BO_ 2667578869 "From abs 21 03, abs 21 21";
CM_ BO_ 2667578870 "From abs 21 42, abs 21 03";
CM_ BO_ 2667578871 "From abs 21 47, abs 21 05, abs 21 06";
CM_ BO_ 2667578872 "From abs 21 05, abs 21 1C, abs 21 0C";
CM_ BO_ 2667578873 "From abs 21 04, abs 21 1F, abs 21 5F";
CM_ BO_ 2667578874 "From abs 21 5A";
CM_ BO_ 2667578875 "From abs 21 5F";
CM_ BO_ 2667578876 "From abs 21 1D, abs 21 1F";
CM_ BO_ 2667578877 "From abs 21 3D";
CM_ BO_ 2667578878 "From abs 21 3F";
CM_ BO_ 2667578879 "From abs 21 3A";
CM_ BO_ 2667578880 "From abs 21 BE";
CM_ BO_ 2667578881 "From abs 21 BE";
CM_ BO_ 2667578882 "From abs 21 BE";
CM_ BO_ 2667578883 "From abs 21 BE";

VAL_ 2667578851 FuelSystemStatus1 0 "Unused" 1 "OL" 2 "CL" 4 "OLDrive" 8 "OLFault" 16 "CLFault" ;
VAL_ 2667578851 FuelSystemStatus2 0 "Unused" 1 "OL" 2 "CL" 4 "OLDrive" 8 "OLFault" 16 "CLFault" ;
VAL_ 2667578854 FuelPumpSpeedControl 0 "OFF" 1 "ON" ;
VAL_ 2667578854 IntankFuelPump 0 "OFF" 1 "ON" ;
VAL_ 2667578859 ElectricFan 0 "OFF" 1 "ON" ;
VAL_ 2667578859 ACClutchRelay 0 "OFF" 1 "ON" ;
VAL_ 2667578859 StarterRelay 0 "OFF" 1 "ON" ;
VAL_ 2667578859 ACCRelay 0 "OFF" 1 "ON" ;
VAL_ 2667578859 ElectricalLoad1 0 "OFF" 1 "ON" ;
VAL_ 2667578860 Shift_P 0 "OFF" 1 "ON" ;
VAL_ 2667578860 Shift_R 0 "OFF" 1 "ON" ;
VAL_ 2667578860 Shift_N 0 "OFF" 1 "ON" ;
VAL_ 2667578860 Shift_D 0 "OFF" 1 "ON" ;
VAL_ 2667578860 Shift_4 0 "OFF" 1 "ON" ;
VAL_ 2667578860 Shift_3 0 "OFF" 1 "ON" ;
VAL_ 2667578860 Shift_2 0 "OFF" 1 "ON" ;
VAL_ 2667578860 Shift_L 0 "OFF" 1 "ON" ;
VAL_ 2667578861 SportsMode 0 "OFF" 1 "ON" ;
VAL_ 2667578861 PaddleUp 0 "OFF" 1 "ON" ;
VAL_ 2667578861 PaddleDown 0 "OFF" 1 "ON" ;
VAL_ 2667578861 Shift_B 0 "OFF" 1 "ON" ;
VAL_ 2667578861 ReverseSwitch 0 "OFF" 1 "ON" ;
VAL_ 2667578861 PatternPWR 0 "OFF" 1 "ON" ;
VAL_ 2667578861 SnowSwitch 0 "OFF" 1 "ON" ;
VAL_ 2667578861 ECOSwitch 0 "OFF" 1 "ON" ;
VAL_ 2667578862 StopLightSwitch 0 "OFF" 1 "ON" ;
VAL_ 2667578862 BrakeSwitch 0 "OFF" 1 "ON" ;
VAL_ 2667578862 BrakeSwitchStatus 0 "Unable" 1 "Able" ;
VAL_ 2667578862 CruiseMain 0 "OFF" 1 "ON" ;
VAL_ 2667578862 CruiseCancel 0 "OFF" 1 "ON" ;
VAL_ 2667578862 CruiseResAcc 0 "OFF" 1 "ON" ;
VAL_ 2667578862 CruiseSetCoast 0 "OFF" 1 "ON" ;
VAL_ 2667578862 KickDown 0 "OFF" 1 "ON" ;
VAL_ 2667578863 StarterSignal 0 "OFF" 1 "ON" ;
VAL_ 2667578863 StarterControl 0 "OFF" 1 "ON" ;
VAL_ 2667578863 ClutchStart 0 "OFF" 1 "ON" ;
VAL_ 2667578863 IdleUp 0 "OFF" 1 "ON" ;
VAL_ 2667578863 ACSignal 0 "OFF" 1 "ON" ;
VAL_ 2667578863 ACPressureNormal 0 "OFF" 1 "ON" ;
VAL_ 2667578863 ACPressureAbnormal 0 "OFF" 1 "ON" ;
VAL_ 2667578863 PowerSteeringSignal 0 "OFF" 1 "ON" ;
VAL_ 2667578864 MIL 0 "OFF" 1 "ON" ;
VAL_ 2667578864 OilPressureSwitch 0 "OFF" 1 "ON" ;
VAL_ 2667578864 FuelCutCondition 0 "OFF" 1 "ON" ;
VAL_ 2667578864 IdleFuelCut 0 "OFF" 1 "ON" ;
VAL_ 2667578864 BrakeOverride 0 "OFF" 1 "ON" ;
VAL_ 2667578864 NeutralControl 0 "OFF" 1 "ON" ;
VAL_ 2667578864 ImmobiliserFuelCut 0 "OFF" 1 "ON" ;
VAL_ 2667578866 ShiftStatus 1 "1st" 2 "2nd" 3 "3rd" 4 "4th" 5 "5th" 6 "6th" 7 "7th" 8 "8th" ;
VAL_ 2667578866 LockUp 0 "OFF" 1 "ON" ;
VAL_ 2667578866 SLT 0 "OFF" 1 "ON" ;
VAL_ 2667578866 SLU 0 "OFF" 1 "ON" ;
VAL_ 2667578866 SLN 0 "OFF" 1 "ON" ;
VAL_ 2667578866 SL 0 "OFF" 1 "ON" ;
VAL_ 2667578866 ST 0 "OFF" 1 "ON" ;
VAL_ 2667578866 SC 0 "OFF" 1 "ON" ;
VAL_ 2667578867 SLS 0 "OFF" 1 "ON" ;
VAL_ 2667578867 SLC 0 "OFF" 1 "ON" ;
VAL_ 2667578867 SLP 0 "OFF" 1 "ON" ;
VAL_ 2667578867 ShiftControlMode 0 "S-mode" 1 "M-mode" ;
VAL_ 2667578867 UpShiftIndication 0 "OFF" 1 "ON" ;
VAL_ 2667578867 DownShiftIndication 0 "OFF" 1 "ON" ;
VAL_ 2667578867 TorqueConverterTempRaiseHistory 0 "OFF" 1 "ON" ;
VAL_ 2667578870 FR_Direction 0 "Forward" 1 "Back" ;
VAL_ 2667578870 FL_Direction 0 "Forward" 1 "Back" ;
VAL_ 2667578870 RR_Direction 0 "Forward" 1 "Back" ;
VAL_ 2667578870 RL_Direction 0 "Forward" 1 "Back" ;
VAL_ 2667578872 GearPosition 0 "Fail" 1 "1st" 2 "2nd" 3 "3rd" 4 "4th" 5 "5th" 6 "6th" 7 "7th" 8 "'P" 9 "8th" 10 "9th" 11 "10th" 14 "R" 15 "Not R" ;
VAL_ 2667578872 ShiftLeverPosition 0 "Fail" 1 "1st" 2 "2nd" 3 "3rd" 4 "4th" 5 "5th" 6 "6th/B" 7 "D/M" 8 "'P" 14 "R" ;
VAL_ 2667578873 StopLightSW 0 "OFF" 1 "ON" ;
VAL_ 2667578873 ParkingBrakeSW 0 "OFF" 1 "ON" ;
VAL_ 2667578873 BrakePedalLoadSW 0 "OFF" 1 "ON" ;
VAL_ 2667578873 DecelerationSW 0 "Fail" 1 "Low" 2 "Mid" 4 "High" ;
VAL_ 2667578873 BrakeAssistCtrl 0 "OFF" 1 "ON" ;
VAL_ 2667578873 PanicBrakeAssistCtrl 0 "OFF" 1 "ON" ;
VAL_ 2667578874 TRC_Ctrl 0 "OFF" 1 "ON" ;
VAL_ 2667578874 TRC_EngineCtrl 0 "OFF" 1 "ON" ;
VAL_ 2667578874 TRC_BrakeCtrl 0 "OFF" 1 "ON" ;
VAL_ 2667578874 TRAC_VSC_OffMode 0 "Normal" 1 "TRC OFF" 2 "VSC Expert Mode" 3 "VSC OFF" ;
VAL_ 2667578874 VSC_FR 0 "OFF" 1 "ON" ;
VAL_ 2667578874 VSC_FL 0 "OFF" 1 "ON" ;
VAL_ 2667578874 VSC_RR 0 "OFF" 1 "ON" ;
VAL_ 2667578874 VSC_RL 0 "OFF" 1 "ON" ;
VAL_ 2667578875 ABS_FR 0 "OFF" 1 "ON" ;
VAL_ 2667578875 ABS_FL 0 "OFF" 1 "ON" ;
VAL_ 2667578875 ABS_RR 0 "OFF" 1 "ON" ;
VAL_ 2667578875 ABS_RL 0 "OFF" 1 "ON" ;
VAL_ 2667578875 EBD_FR 0 "OFF" 1 "ON" ;
VAL_ 2667578875 EBD_FL 0 "OFF" 1 "ON" ;
VAL_ 2667578875 EBD_RR 0 "OFF" 1 "ON" ;
VAL_ 2667578875 EBD_RL 0 "OFF" 1 "ON" ;
VAL_ 2667578876 TRC_VSC_OffSwitch 0 "OFF" 1 "ON" ;
VAL_ 2667578876 ReservoirWarning 0 "OFF" 1 "ON" ;
VAL_ 2667578876 MainIdle 0 "OFF" 1 "ON" ;
VAL_ 2667578876 AutoLSD 0 "OFF" 1 "ON" ;
VAL_ 2667578876 A_TRC 0 "OFF" 1 "ON" ;
VAL_ 2667578876 DownhillAssist 0 "OFF" 1 "ON" ;
VAL_ 2667578876 PreCrashBrakeOff 0 "OFF" 1 "ON" ;
VAL_ 2667578876 FourWD 0 "OFF" 1 "ON" ;
VAL_ 2667578877 ABS_Light 0 "OFF" 1 "ON" ;
VAL_ 2667578877 Brake_Light 0 "OFF" 1 "ON" ;
VAL_ 2667578877 Slip_Light 0 "OFF" 1 "ON" ;
VAL_ 2667578877 Buzzer 0 "OFF" 1 "ON" ;
VAL_ 2667578877 TirePressure_Light 0 "OFF" 1 "ON" ;
VAL_ 2667578877 VSC_Light 0 "OFF" 1 "ON" ;
VAL_ 2667578877 AutoLSD_Light 0 "OFF" 1 "ON" ;
VAL_ 2667578877 A_TRAC_Light 0 "OFF" 1 "ON" ;
VAL_ 2667578878 Solenoid_SFRH 0 "OFF" 1 "ON" ;
VAL_ 2667578878 Solenoid_SFRR 0 "OFF" 1 "ON" ;
VAL_ 2667578878 Solenoid_SFLH 0 "OFF" 1 "ON" ;
VAL_ 2667578878 Solenoid_SFLR 0 "OFF" 1 "ON" ;
VAL_ 2667578878 Solenoid_SRRH 0 "OFF" 1 "ON" ;
VAL_ 2667578878 Solenoid_SRRR 0 "OFF" 1 "ON" ;
VAL_ 2667578878 Solenoid_SRLH 0 "OFF" 1 "ON" ;
VAL_ 2667578878 Solenoid_SRLR 0 "OFF" 1 "ON" ;
VAL_ 2667578879 Solenoid_SPFL 0 "OFF" 1 "ON" ;
VAL_ 2667578879 Solenoid_SPFR 0 "OFF" 1 "ON" ;
VAL_ 2667578879 Solenoid_SM2 0 "OFF" 1 "ON" ;
VAL_ 2667578879 Solenoid_SM1 0 "OFF" 1 "ON" ;
VAL_ 2667578879 Solenoid_SRM2 0 "OFF" 1 "ON" ;
VAL_ 2667578879 Solenoid_SRM1 0 "OFF" 1 "ON" ;
VAL_ 2667578879 Solenoid_SRC2 0 "OFF" 1 "ON" ;
VAL_ 2667578879 Solenoid_SRC1 0 "OFF" 1 "ON" ;
VAL_ 2667578880 FR_SpeedOpen 0 "Normal" 1 "Error" ;
VAL_ 2667578880 FL_SpeedOpen 0 "Normal" 1 "Error" ;
VAL_ 2667578880 RR_SpeedOpen 0 "Normal" 1 "Error" ;
VAL_ 2667578880 RL_SpeedOpen 0 "Normal" 1 "Error" ;
VAL_ 2667578880 EFI_CommOpen 0 "Normal" 1 "Error" ;
VAL_ 2667578880 YawRateOpen 0 "Normal" 1 "Error" ;
VAL_ 2667578880 DecelerationOpen 0 "Normal" 1 "Error" ;
VAL_ 2667578880 SteeringOpen 0 "Normal" 1 "Error" ;
VAL_ 2667578881 MasterCylinderOpen 0 "Normal" 1 "Error" ;
VAL_ 2667578881 MasterCylinder2Open 0 "Normal" 1 "Error" ;
VAL_ 2667578881 StrokeOpen 0 "Normal" 1 "Error" ;
VAL_ 2667578881 Stroke2Open 0 "Normal" 1 "Error" ;
VAL_ 2667578881 FR_WheelCylinderOpen 0 "Normal" 1 "Error" ;
VAL_ 2667578881 FL_WheelCylinderOpen 0 "Normal" 1 "Error" ;
VAL_ 2667578881 RR_WheelCylinderOpen 0 "Normal" 1 "Error" ;
VAL_ 2667578881 RL_WheelCylinderOpen 0 "Normal" 1 "Error" ;
VAL_ 2667578882 AccumulatorOpen 0 "Normal" 1 "Error" ;
VAL_ 2667578882 HV_CommOpen 0 "Normal" 1 "Error" ;
VAL_ 2667578882 IG_VoltageDecreased 0 "Normal" 1 "Error" ;
VAL_ 2667578882 IG_VoltageIncreased 0 "Normal" 1 "Error" ;
VAL_ 2667578882 FR_SpeedVoltageOpen 0 "Normal" 1 "Error" ;
VAL_ 2667578882 FL_SpeedVoltageOpen 0 "Normal" 1 "Error" ;
VAL_ 2667578882 RR_SpeedVoltageOpen 0 "Normal" 1 "Error" ;
VAL_ 2667578882 RL_SpeedVoltageOpen 0 "Normal" 1 "Error" ;
VAL_ 2667578883 MC_SensorNoise 0 "Normal" 1 "Error" ;
VAL_ 2667578883 BrakePedalSwitchOpen 0 "Normal" 1 "Error" ;
VAL_ 2667578883 YawRateVoltageOpen 0 "Normal" 1 "Error" ;
VAL_ 2667578883 EFI_CommInvalid 0 "Normal" 1 "Error" ;
VAL_ 2667578883 VerticalGOpen 0 "Normal" 1 "Error" ;
VAL_ 2667578883 BodyECU_CommOpen 0 "Normal" 1 "Error" ;
VAL_ 2667578883 MC_SensorSupplyOpen 0 "Normal" 1 "Error" ;
VAL_ 2667578883 SolenoidSupplyOpen 0 "Normal" 1 "Error" ;
